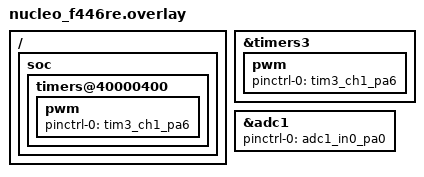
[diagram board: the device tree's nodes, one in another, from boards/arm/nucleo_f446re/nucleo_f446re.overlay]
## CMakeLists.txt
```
# SPDX-License-Identifier: Apache-2.0

cmake_minimum_required(VERSION 3.20.0)

find_package(Zephyr REQUIRED HINTS $ENV{ZEPHYR_BASE})
project(UART_Command_Center)

target_sources(app PRIVATE src/main.c
            src/uart_handler.c
            src/menu/menu_core.c
            src/menu/menu_actions.c
            src/menu/menu_display.c
            src/commands/commands_core.c
            src/drivers/lights_control.c
            src/commands/command_lights.c
            src/commands/command_sensors.c
)
target_include_directories(app PRIVATE ${CMAKE_CURRENT_SOURCE_DIR}/include)
```

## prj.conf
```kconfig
CONFIG_SERIAL=y
CONFIG_UART_INTERRUPT_DRIVEN=y
# CONFIG_ZTEST=y
# CONFIG_ZTEST_ASSERT_VERBOSE=1
CONFIG_LOG=y
CONFIG_LOG_DEFAULT_LEVEL=4
CONFIG_PWM=y
CONFIG_PWM_STM32=y
CONFIG_ADC=y
CONFIG_I2C=y
```

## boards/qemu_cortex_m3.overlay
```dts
&{/soc} {
    fake_tim3: timers3 {
        compatible = "test-fake-pwm";
        status = "okay";
    };
};
```

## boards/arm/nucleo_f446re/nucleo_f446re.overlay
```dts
/* devicetree.overlay */

/ {
    /* Path-based override is optional. Usually you can just do &timers3. */
	soc {
		timers@40000400 {
			status = "okay";

			pwm {
				status = "okay";
				pinctrl-0 = <&tim3_ch1_pa6>;
				pinctrl-names = "default";
			};
		};
    };
};

/* Or using the node label directly: */
&timers3 {
    status = "okay";

    pwm {
        status = "okay";
        pinctrl-0 = <&tim3_ch1_pa6>;
        pinctrl-names = "default";
    };
};

&adc1 {
    status = "okay";
    pinctrl-0 = <&adc1_in0_pa0>;
    pinctrl-names = "default";
};
```

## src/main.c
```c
#include "uart_handler.h"
#include "menu.h"

int main(void)
{
    int ret = uart_handler_init();
    if (ret < 0) {
        printk("Failed to initialize UART handler\n");
        return 0;
    }

    // Optionally print a welcome message
    uart_handler_write_string("Welcome! Starting the menu...\r\n");

    // Run the main menu loop
    menu_core_run();

    // If the user exits the menu:
    uart_handler_write_string("Menu exited. Shutting down.\r\n");
    return 0;
}
```

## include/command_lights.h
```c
/**
 * @file command_lights.h
 * @brief Lights command interface.
 * 
 * Description:
 * ------------
 * This header provides the function prototype for executing lights-related 
 * commands. It is included by commands_core.c to integrate lights functionality 
 * with the top-level command execution framework.
 * 
 * By separating lights commands here, we keep code modular, maintainable, and 
 * easy to expand with additional lights operations in the future.
 * 
 * Author: Ameed Othman
 * Date: 2024-12-20
 */

#ifndef COMMAND_LIGHTS_H__
#define COMMAND_LIGHTS_H__

#ifdef __cplusplus
extern "C" {
#endif

/**
 * @brief Execute a lights-specific command.
 *
 * @param action_id The ID of the lights action to execute.
 *                  Example: 0=Turn ON, 1=Turn OFF, etc.
 */
void command_lights_execute(int action_id);

#ifdef __cplusplus
}
#endif

#endif /* COMMAND_LIGHTS_H__ */
```

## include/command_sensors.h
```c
/**
* @file command_sensors.h
* @brief Sensors command interface.
*
* Description:
* ------------
* This header defines the public interface for executing sensors-related commands.
* It is included by `commands_core.c` and other modules that need to trigger
* sensors actions by calling `command_sensors_execute()`.
*
* By abstracting sensors commands here, we keep code modular, maintainable, and
* easy to expand with additional sensor operations in the future.
*
* Typical Actions:
* ----------------
*  action_id=0: Read temperature
*  action_id=1: Read humidity
* Additional actions can be easily added as needed.
*
* @author Ameed Othman
* @date 2024-12-21
*/

#ifndef COMMAND_SENSORS_H__
#define COMMAND_SENSORS_H__

#ifdef __cplusplus
extern "C" {
#endif

    /**
     * @brief Execute a sensors command.
     *
     * Called by the commands subsystem when a command in the sensors category
     * (category=2) is requested. The action_id parameter determines which sensor
     * reading to perform or which sensor-related action to execute.
     *
     * @param action_id The sensors command action (e.g., 0=read temperature, 1=read humidity).
     */
    void command_sensors_execute(int action_id);

#ifdef __cplusplus
}
#endif

#endif /* COMMAND_SENSORS_H__ */
```

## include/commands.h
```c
/**
 * @file commands.h
 * @brief Command execution interface.
 * 
 * @author Ameed Othman
 * @date 2024-12-19
 */

#ifndef COMMANDS_H__
#define COMMANDS_H__

#ifdef __cplusplus
extern "C" {
#endif

/**
 * @brief Execute a command based on category and action_id.
 *
 * @param category Command category (1=Lights, 2=Sensors, 3=System, 4=Diagnostics)
 * @param action_id Specific action within the category.
 */
int commands_core_execute(int category, int action_id);

#ifdef __cplusplus
}
#endif

#endif /* COMMANDS_H__ */
```

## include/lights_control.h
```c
/*
 * Copyright (c) 2024 UARTCommandCenter
 *
 * SPDX-License-Identifier: Apache-2.0
 *
 * @file lights_control.h
 * @brief Public interface for controlling lights.
 * 
 * Description:
 * ------------
 * This header defines the public interface for the lights control driver.
 * It provides function prototypes for turning lights on/off, adjusting 
 * brightness levels, and querying their current state.
 *
 * @author Ameed Othman
 * @date 2024-12-20
 */

#ifndef LIGHTS_CONTROL_H__
#define LIGHTS_CONTROL_H__

#include <stdbool.h>
#include <zephyr/kernel.h>  /* For return types like int */

/* C++ support */
#ifdef __cplusplus
extern "C" {
#endif

/**
 * @brief Initialize the lights control subsystem.
 *
 * Prepares any necessary hardware interfaces (e.g., GPIO, PWM) or internal state
 * related to controlling the lights. If no hardware initialization is needed, 
 * this may simply set up default values.
 *
 * @return 0 on success, or a negative error code if initialization fails.
 */
int lights_control_init(void);

/**
 * @brief Turn the lights ON.
 *
 * Activates whatever hardware mechanism is required to illuminate the lights.
 * In a simple LED scenario, this might set a GPIO pin high or enable a PWM output.
 *
 * @return 0 on success, or a negative error code if the operation fails.
 */
int lights_control_turn_on(void);

/**
 * @brief Turn the lights OFF.
 *
 * Deactivates the lights. For LEDs, this might mean setting a GPIO pin low or 
 * disabling a PWM output channel.
 *
 * @return 0 on success, or a negative error code if the operation fails.
 */
int lights_control_turn_off(void);

/**
 * @brief Increase the brightness level of the lights.
 *
 * Adjusts the lights to a higher brightness setting, if supported. For a PWM-based
 * LED system, this might increase the duty cycle. The implementation should 
 * ensure brightness does not exceed the maximum allowed level (e.g., 100%).
 *
 * @return 0 on success, or a negative error code if the operation fails.
 */
int lights_control_increase_brightness(void);

/**
 * @brief Decrease the brightness level of the lights.
 *
 * Adjusts the lights to a lower brightness setting. The implementation should 
 * ensure brightness does not go below zero. If the lights are already at minimum 
 * brightness, this operation can either do nothing or log a message indicating 
 * no further reduction is possible.
 *
 * @return 0 on success, or a negative error code if the operation fails.
 */
int lights_control_decrease_brightness(void);

/**
 * @brief Retrieve the current lights state.
 *
 * Queries whether the lights are currently ON or OFF, and what the current 
 * brightness level is. Brightness is typically represented as a percentage (0-100%).
 *
 * @param state Pointer to a bool that will receive the ON/OFF state. True = ON, False = OFF.
 * @param level Pointer to an int that will receive the brightness level (e.g., 0-100).
 *
 * @return 0 on success, or a negative error code if invalid parameters are provided 
 * or the operation fails for some reason.
 */
int lights_control_get_state(bool *state, int *level);

#ifdef __cplusplus
}
#endif

#endif /* LIGHTS_CONTROL_H__ */
```

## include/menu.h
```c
#ifndef MENU_H__
#define MENU_H__

#ifdef __cplusplus
extern "C" {
#endif

void menu_core_run(void);

#ifdef __cplusplus
}
#endif

#endif /* MENU_H__ */
```

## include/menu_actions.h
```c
/**
 * @file menu_actions.h
 * @brief Menu action execution.
 * 
 * Description:
 * ------------
 * 
 * This file handles the execution of menu-related actions triggered by user input 
 * from the menu system. It acts as a dispatch center that translates user choices 
 * into meaningful operations, such as toggling lights, reading sensors, or 
 * adjusting system configurations.
 * 
 * @author Ameed Othman
 * @date 2024-12-20
 */

#ifndef MENU_ACTIONS_H__
#define MENU_ACTIONS_H__

#ifdef __cplusplus
extern "C" {
#endif

/**
 * @brief Execute a menu action based on a given category and action ID.
 *
 * This function is the interface from the menu system to the command execution layer.
 * It takes a category (e.g., lights=1, sensors=2, etc.) and an action_id, and then
 * delegates to the appropriate command logic via commands_core_execute().
 *
 * @param category The category of action (1=Lights, 2=Sensors, 3=System, 4=Diagnostics).
 * @param action_id Specific action ID within that category.
 */
void menu_actions_execute(int category, int action_id);

#ifdef __cplusplus
}
#endif

#endif /* MENU_ACTIONS_H__ */
```

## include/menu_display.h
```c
/**
 * @file menu_display.h
 * @brief Menu display functions.
 * 
 * Description:
 * ------------
 * 
 * This file provides functions to display menus and messages to the user via UART. 
 * 
 * @author Ameed Othman
 * @date 2024-12-20
 */

#ifndef MENU_DISPLAY_H__
#define MENU_DISPLAY_H__

#ifdef __cplusplus
extern "C" {
#endif

/**
 * @brief Show the main menu options to the user.
 *
 * This function prints a predefined list of main menu items.
 */
void menu_display_show_main_menu(void);

/**
 * @brief Print a generic message to the user via UART.
 *
 * This function is used by other parts of the menu system to present 
 * simple prompts, instructions, or feedback messages.
 *
 * @param msg A null-terminated string containing the message to print.
 */
void menu_display_message(const char *msg);

/**
 * @brief Print an error message indicating invalid input or similar conditions.
 *
 * A dedicated function for errors allows distinct styling or logging.
 *
 * @param err_msg A null-terminated string describing the error condition.
 */
void menu_display_error(const char *err_msg);

#ifdef __cplusplus
}
#endif

#endif /* MENU_DISPLAY_H__ */
```

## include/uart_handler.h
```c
/*
 * Copyright (c) 2024 UARTCommandCenter
 *
 * SPDX-License-Identifier: Apache-2.0
 *
 * @file uart_handler.h
 * @brief UART handler public interface.
 * 
 * Description:
 * This header provides the public interface for UART handling functionality.
 * The UART handler is responsible for:
 *   - Initializing the UART interface with interrupt-driven reception.
 *   - Providing a message queue from which complete input lines can be retrieved.
 *   - Offering utility functions to write strings to the UART output.
 *
 * Other modules can interact with the UART via these functions, enabling line-based
 * command parsing and interactive menus over UART.
 * 
 * @author Ameed Othman
 * @date 2024-12-19
 */

#ifndef UART_HANDLER_H__
#define UART_HANDLER_H__

#include <zephyr/kernel.h>

#ifdef __cplusplus
extern "C" {
#endif

/**
 * @brief Initialize the UART subsystem.
 *
 * This function configures the UART device for interrupt-driven reception,
 * sets the IRQ callback, and enables RX interrupts. It should be called
 * once during startup before using any other UART handler functions.
 *
 * @return 0 on success, or a negative error code on failure.
 */
int uart_handler_init(void);

/**
 * @brief Write a null-terminated string to the UART output.
 *
 * Sends the given string over UART using polling mode. This function is
 * best used for relatively short messages, such as prompts, logging messages,
 * or status updates. For large amounts of data, consider implementing a
 * buffered or DMA-based solution.
 *
 * @param str A null-terminated string to send.
 * @return 0 on success, or a negative error code on invalid parameters.
 */
int uart_handler_write_string(const char *str);

/**
 * @brief Externally accessible message queue for retrieved UART lines.
 *
 * The UART handler pushes complete lines (terminated by newline or carriage return)
 * into this queue. Other application components (e.g., menu systems or command
 * parsers) can retrieve lines non-blocking or blocking using `k_msgq_get()`.
 *
 * Usage example:
 * @code
 *   char line_buffer[LINE_SIZE];
 *   if (k_msgq_get(&uart_msgq, line_buffer, K_FOREVER) == 0) {
 *       // Process the retrieved line
 *   }
 * @endcode
 *
 * Note:
 * The size of the queue elements and the number of messages, as well as the line buffer size,
 * should be defined in app_config.h or uart_handler.c as per design.
 */
extern struct k_msgq uart_msgq;

#ifdef __cplusplus
}
#endif

#endif /* UART_HANDLER_H__ */
```

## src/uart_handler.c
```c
/*
 * Copyright (c) 2024 UARTCommandCenter
 *
 * SPDX-License-Identifier: Apache-2.0
 *
 * @file uart_handler.c
 * @brief UART handler implementation.
 * 
 * Description:
 * This file provides UART handling functionality, including initialization,
 * interrupt-driven data reception, and utility functions to send strings
 * over UART. The UART handler uses a message queue to store incoming lines,
 * making them available for higher-level logic such as command parsing
 * and menu navigation.
 * 
 * @author Ameed Othman
 * @date 2024-12-19
 */

#include <zephyr/kernel.h>
#include <zephyr/device.h>
#include <zephyr/drivers/uart.h>
#include <zephyr/logging/log.h>
#include <string.h>

#include "app_config.h"
#include "uart_handler.h"

/* 
 * LOG_MODULE_REGISTER allows runtime control of log level.
 * Make sure CONFIG_LOG is enabled in prj.conf.
 */
LOG_MODULE_REGISTER(uart_handler, LOG_LEVEL_INF);

/* Fetch the UART device from the chosen node */
#define UART_DEVICE_NODE DT_CHOSEN(zephyr_shell_uart)
static const struct device *uart_dev = DEVICE_DT_GET(UART_DEVICE_NODE);

/* 
 * Buffer for incoming characters before a newline is received.
 * MSG_SIZE and related constants could be defined in app_config.h
 * for consistency and flexibility.
 */
#ifndef UART_MSG_SIZE
#define UART_MSG_SIZE 64
#endif

#ifndef UART_MSGQ_LEN
#define UART_MSGQ_LEN 10
#endif

/* Message queue to hold complete lines received via UART */
K_MSGQ_DEFINE(uart_msgq, UART_MSG_SIZE, UART_MSGQ_LEN, 4);

/* Internal receive buffer and position index */
static char rx_buf[UART_MSG_SIZE];
static size_t rx_buf_pos = 0;

/* Forward declaration of the interrupt callback */
static void uart_irq_handler(const struct device *dev, void *user_data);

/**
 * @brief Initialize the UART subsystem.
 *
 * This function configures the UART device for interrupt-driven reception and
 * sets up the ISR callback. It must be called before using any other UART handler
 * functions.
 *
 * @return 0 if initialization is successful, or a negative error code otherwise.
 */
int uart_handler_init(void)
{
	if (!device_is_ready(uart_dev)) {
		LOG_ERR("UART device not ready");
		return -ENODEV;
	}

	int ret = uart_irq_callback_user_data_set(uart_dev, uart_irq_handler, NULL);
	if (ret < 0) {
		LOG_ERR("Failed to set UART callback (err %d)", ret);
		return ret;
	}

	uart_irq_rx_enable(uart_dev);
	LOG_INF("UART initialized and RX interrupt enabled");

	return 0;
}

/**
 * @brief Write a string to the UART output.
 *
 * This function sends a null-terminated string via UART using polling mode.
 * It should be used sparingly for short messages (e.g., prompts, logs).
 *
 * @param str A null-terminated string to send.
 * @return 0 on success, or a negative error code on failure.
 */
int uart_handler_write_string(const char *str)
{
	if (!uart_dev || !str) {
		return -EINVAL;
	}

	size_t len = strlen(str);
	for (size_t i = 0; i < len; i++) {
		uart_poll_out(uart_dev, str[i]);
	}

	return 0;
}

/**
 * @brief Attempt to read a complete line from the UART message queue.
 *
 * This is not a required function, but it demonstrates how higher-level modules
 * might interface with the UART handler. It is not declared in the header since
 * it’s optional. Higher-level code may use k_msgq_get() directly on uart_msgq.
 *
 * @param buffer A pointer to a buffer to store the line.
 * @param timeout Kernel timeout for waiting on a complete line.
 * @return 0 on success, or -EAGAIN if no data is available before timeout.
 */
static int uart_handler_read_line(char *buffer, k_timeout_t timeout)
{
	if (!buffer) {
		return -EINVAL;
	}

	return k_msgq_get(&uart_msgq, buffer, timeout);
}

/* 
 * UART interrupt callback:
 * Reads characters from the UART hardware until FIFO is empty.
 * If a newline is encountered, the accumulated line is pushed onto the message queue.
 * Characters beyond the buffer size are dropped to prevent overflow.
 */
static void uart_irq_handler(const struct device *dev, void *user_data)
{
	ARG_UNUSED(user_data);

	if (!uart_irq_update(uart_dev)) {
		return;
	}

	if (!uart_irq_rx_ready(uart_dev)) {
		return;
	}

	uint8_t c;
	while (uart_fifo_read(uart_dev, &c, 1) == 1) {
		/* Check for end-of-line */
		if ((c == '\n' || c == '\r') && rx_buf_pos > 0) {
			rx_buf[rx_buf_pos] = '\0';
			int ret = k_msgq_put(&uart_msgq, rx_buf, K_NO_WAIT);
			if (ret < 0) {
				LOG_WRN("UART message queue full. Dropping input line.");
			}
			rx_buf_pos = 0;
		} else if (rx_buf_pos < (UART_MSG_SIZE - 1)) {
			rx_buf[rx_buf_pos++] = (char)c;
		} else {
			/* Buffer full, drop any additional characters until a newline arrives */
			/* Optional: could log this event if needed */
		}
	}
}

/* End of uart_handler.c */
```
